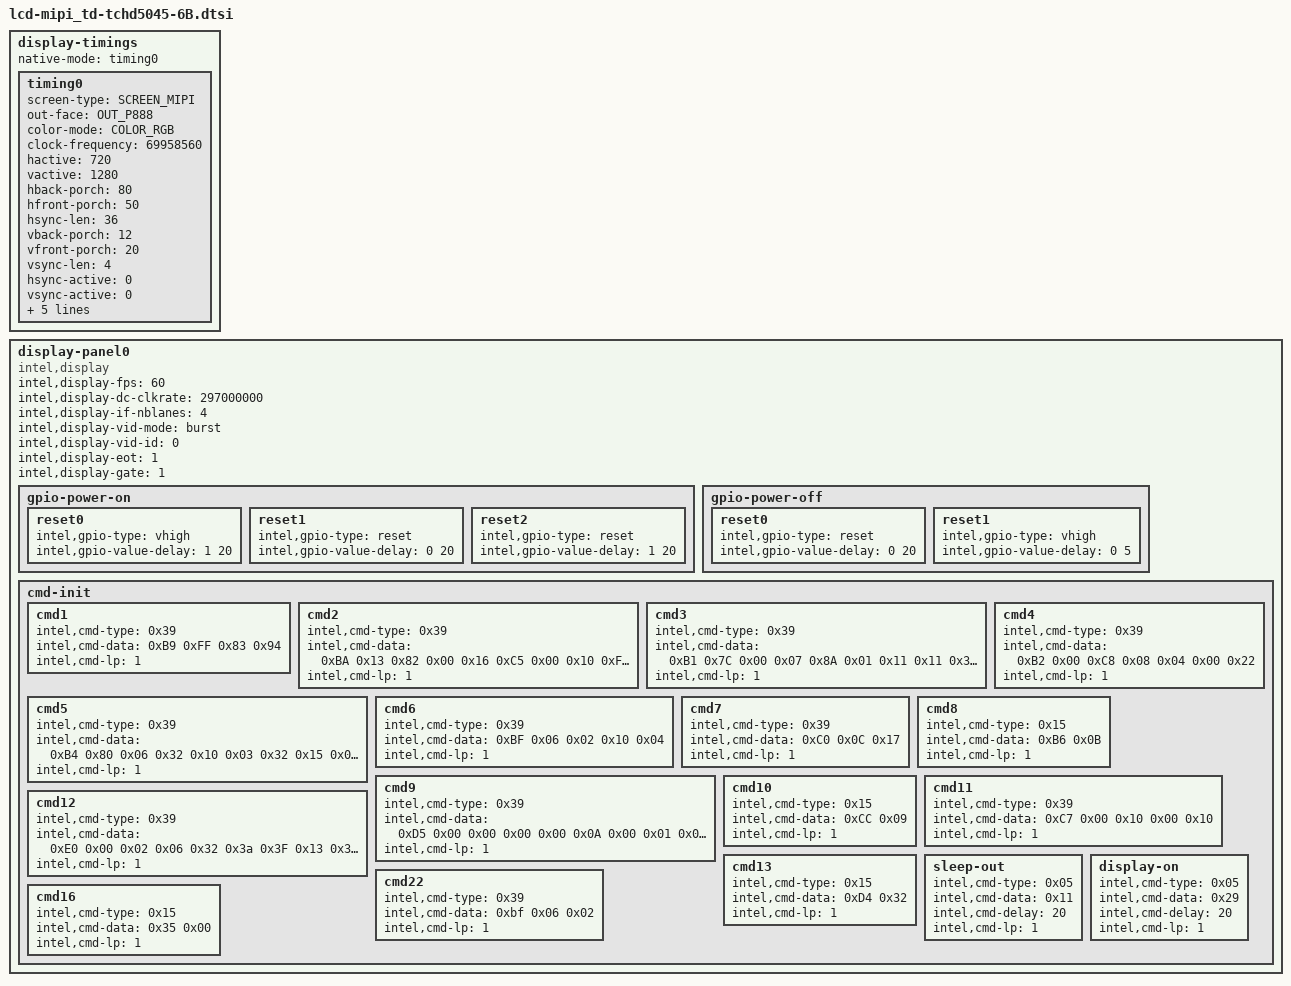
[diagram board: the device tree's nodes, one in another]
/*
 * sofia: lcd-mipi_td-tchd5045-6B.dtsi
 * definition at "include/dt-bindings/sofiafb/sofia_fb.h"
 */

	display-timings {
		native-mode = <&timing0>;
		timing0: timing0 {
			screen-type = <SCREEN_MIPI>;
			out-face = <OUT_P888>;
			color-mode = <COLOR_RGB>;
			clock-frequency = <69958560>;
			hactive = <720>;
			vactive = <1280>;
			hback-porch = <80>;
			hfront-porch = <50>;
			hsync-len = <36>;
			vback-porch = <12>;
			vfront-porch = <20>;
			vsync-len = <4>;
			hsync-active = <0>;
			vsync-active = <0>;
			de-active = <0>;
			pixelclk-active = <0>;
			swap-rb = <0>;
			swap-rg = <0>;
			swap-gb = <0>;
		};
	};

	display-panel0 {
		compatible = "intel,display";

		/* intel,display-ramless = <1>; */
		intel,display-fps = <60>;
		intel,display-dc-clkrate = <297000000>;
		intel,display-if-nblanes = <4>;
		intel,display-vid-mode = "burst";
		intel,display-vid-id = <0>;
		intel,display-eot = <1>;
		intel,display-gate = <1>;

		gpio-power-on {
			reset0 {
				intel,gpio-type = "vhigh";
				intel,gpio-value-delay = <1 20>;
			};
			reset1 {
				intel,gpio-type = "reset";
				intel,gpio-value-delay = <0 20>;
			};
			reset2 {
				intel,gpio-type = "reset";
				intel,gpio-value-delay = <1 20>;
			};
		};

		gpio-power-off {
			reset0 {
				intel,gpio-type = "reset";
				intel,gpio-value-delay = <0 20>;
			};
			reset1 {
				intel,gpio-type = "vhigh";
				intel,gpio-value-delay = <0 5>;
			};
		};

		cmd-init {
			cmd1 {
				intel,cmd-type = <0x39>;
				intel,cmd-data = <0xB9 0xFF 0x83 0x94>;
				intel,cmd-lp = <1>;
			};
			cmd2 {
				intel,cmd-type = <0x39>;
				intel,cmd-data = <0xBA 0x13 0x82 
				0x00 0x16 0xC5 0x00 0x10 0xFF 0x0F 
				0x24 0x03 0x21 0x24 0x25 0x20 0x08>;
				intel,cmd-lp = <1>;
			};
			cmd3 {
				intel,cmd-type = <0x39>;
				intel,cmd-data = <0xB1 0x7C 0x00 0x07
				0x8A 0x01 0x11 0x11 0x38 0x3D 0x3F 
				0x3F 0x47 0x12 0x01 0xE6 0xE2>;
				intel,cmd-lp = <1>;
			};
			cmd4 {
				intel,cmd-type = <0x39>;
				intel,cmd-data = <0xB2 0x00 0xC8 0x08 0x04 0x00 0x22>;
				intel,cmd-lp = <1>;
			};
			cmd5 {
				intel,cmd-type = <0x39>;
				intel,cmd-data = <0xB4 0x80 0x06 
				0x32 0x10 0x03 0x32 0x15 0x08 0x32 
				0x10 0x08 0x33 0x04 0x43 0x05 0x37 
				0x04 0x43 0x06 0x61 0x61 0x06>;
				intel,cmd-lp = <1>;
			};
			cmd6 {
				intel,cmd-type = <0x39>;
				intel,cmd-data = <0xBF 0x06 0x02 0x10 0x04>;
				intel,cmd-lp = <1>;
			};
			cmd7 {
				intel,cmd-type = <0x39>;
				intel,cmd-data = <0xC0 0x0C 0x17>;
				intel,cmd-lp = <1>;
			};
			cmd8 {
				intel,cmd-type = <0x15>;
				intel,cmd-data = <0xB6 0x0B>;
				intel,cmd-lp = <1>;
			};
			cmd9 {
				intel,cmd-type = <0x39>;
				intel,cmd-data = <0xD5 0x00 0x00
				0x00 0x00 0x0A 0x00 0x01 0x00 
				0xCC 0x00 0x00 0x00 0x88 0x88
				0x88 0x88 0x88 0x88 0x88 0x88
				0x88 0x88 0x01 0x67 0x45 0x23
				0x01 0x23 0x88 0x88 0x88 0x88>;
				intel,cmd-lp = <1>;
			};	
			cmd10 {
				intel,cmd-type = <0x15>;
				intel,cmd-data = <0xCC 0x09>;
				intel,cmd-lp = <1>;
			};
			cmd11 {
				intel,cmd-type = <0x39>;
				intel,cmd-data = <0xC7 0x00 0x10 0x00 0x10>;
				intel,cmd-lp = <1>;
			};
			cmd12 {
				intel,cmd-type = <0x39>;
				intel,cmd-data = <0xE0 0x00 0x02 0x06 
				0x32 0x3a 0x3F 0x13 0x35 0x08 0x0d 
				0x0e 0x10 0x13 0x11 0x13 0x10 0x17 
				0x00 0x02 0x06 0x32 0x3a 0x3F 0x13
				0x35 0x08 0x0d 0x0e 0x10 0x13 0x11 
				0x13 0x10 0x17 0x09 0x16 0x07 0x11
				0x09 0x16 0x07 0x11>;
				intel,cmd-lp = <1>;
			};
			cmd13 {
				intel,cmd-type = <0x15>;
				intel,cmd-data = <0xD4 0x32>;
				intel,cmd-lp = <1>;
			};

			sleep-out {
				intel,cmd-type = <0x05>;
				intel,cmd-data = <0x11>;
				intel,cmd-delay = <20>;
				intel,cmd-lp = <1>;
			};
			display-on {
				intel,cmd-type = <0x05>;
				intel,cmd-data = <0x29>;
				intel,cmd-delay = <20>;
				intel,cmd-lp = <1>;
			};

			cmd22 {
				intel,cmd-type = <0x39>;
				intel,cmd-data = <0xbf 0x06 0x02>; 
				intel,cmd-lp = <1>;
			};
            //TE
			cmd16 {
				intel,cmd-type = <0x15>;
				intel,cmd-data = <0x35 0x00>;
				intel,cmd-lp = <1>;
			};			
		};
/*
		cmd-sleep-in {
			display-off {
				intel,cmd-type = <0x05>;
				intel,cmd-data = <0x28>;
				intel,cmd-delay = <120>;
				intel,cmd-lp = <1>;
			};
			sleep-in {
				intel,cmd-type = <0x05>;
				intel,cmd-data = <0x10>;
				intel,cmd-delay = <20>;
				intel,cmd-lp = <1>;
			};
		};
		cmd-sleep-out {
			sleep-out {
				intel,cmd-type = <0x05>;
				intel,cmd-data = <0x11>;
				intel,cmd-delay = <120>;
				intel,cmd-lp = <1>;
			};
			display-on {
				intel,cmd-type = <0x05>;
				intel,cmd-data = <0x29>;
				intel,cmd-delay = <120>;
				intel,cmd-lp = <1>;
			};
		};
*/
	};
